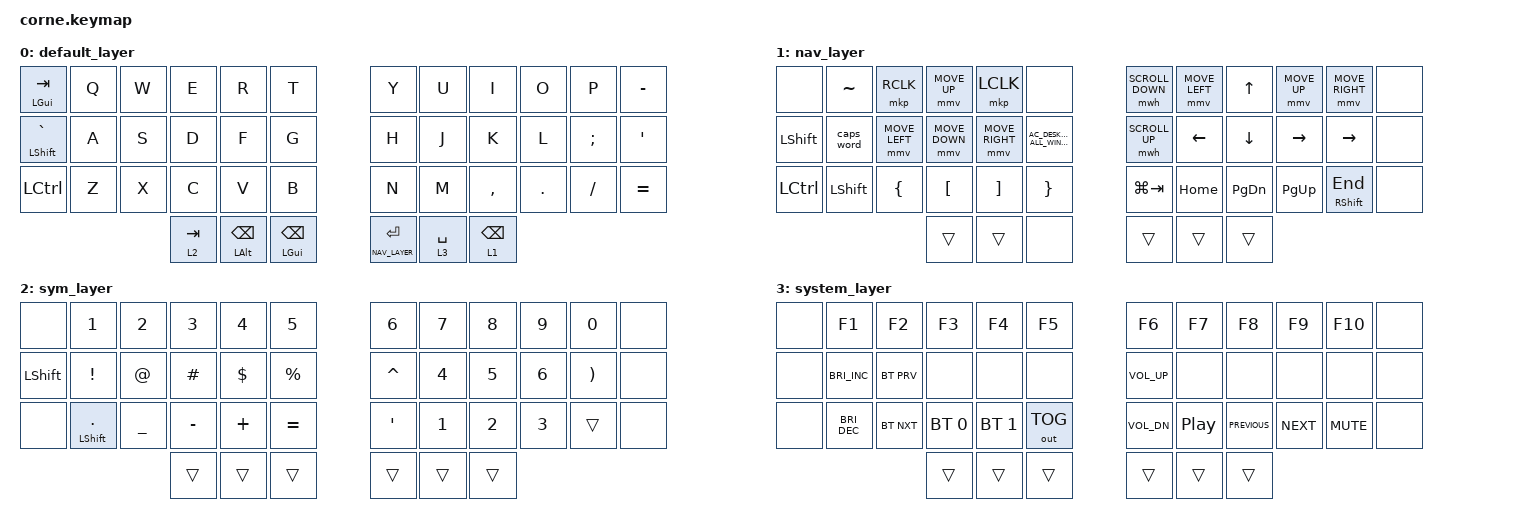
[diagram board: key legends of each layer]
/*
 * Copyright (c) 2020 The ZMK Contributors
 *
 * SPDX-License-Identifier: MIT
 */

#include <behaviors.dtsi>
#include <dt-bindings/zmk/mouse.h>
#include <dt-bindings/zmk/bt.h>
#include <dt-bindings/zmk/keys.h>
#include <dt-bindings/zmk/outputs.h>

#undef MOVE_UP
#undef MOVE_DOWN
#undef MOVE_LEFT
#undef MOVE_RIGHT

#define MOVE_UP MOVE_VERT(-6000)
#define MOVE_DOWN MOVE_VERT(6000)
#define MOVE_LEFT MOVE_HOR(-6000)
#define MOVE_RIGHT MOVE_HOR(6000)

#undef SCROLL_UP
#undef SCROLL_DOWN

#define SCROLL_UP SCROLL_VERT(40)
#define SCROLL_DOWN SCROLL_VERT(-40)
#define NAV_LAYER 1
#define SYM_LAYER 2
#define SYSTEM_LAYER 3

&mmv { time-to-max-speed-ms = <500>; };

&mwh { time-to-max-speed-ms = <500>; };

/ {
    behaviors {
        ht: holdtap {
            compatible = "zmk,behavior-hold-tap";
            label = "THUMB_HOLD_TAPS";
            #binding-cells = <2>;
            tapping-term-ms = <300>;
            flavor = "balanced";
            global-quick-tap;
            quick-tap-ms = <0>;
            bindings = <&kp>, <&kp>;
        };
    };

    macros {
        ae: ae {
            label = "ä";
            compatible = "zmk,behavior-macro";
            #binding-cells = <0>;
            wait-ms = <40>;
            tap-ms = <40>;
            bindings =
                <&macro_press>,
                <&kp LALT>,
                <&macro_tap>,
                <&kp U>,
                <&macro_release>,
                <&kp LALT>,
                <&macro_tap>,
                <&kp A>;
        };

        oe: oe {
            label = "ö";
            compatible = "zmk,behavior-macro";
            #binding-cells = <0>;
            wait-ms = <40>;
            tap-ms = <40>;
            bindings =
                <&macro_press>,
                <&kp LALT>,
                <&macro_tap>,
                <&kp U>,
                <&macro_release>,
                <&kp LALT>,
                <&macro_tap>,
                <&kp O>;
        };

        cae: cae {
            label = "Ä";
            compatible = "zmk,behavior-macro";
            #binding-cells = <0>;
            wait-ms = <40>;
            tap-ms = <40>;
            bindings =
                <&macro_press>,
                <&kp LALT>,
                <&macro_tap>,
                <&kp U>,
                <&macro_release>,
                <&kp LALT>,
                <&macro_press>,
                <&kp LSHFT>,
                <&macro_tap>,
                <&kp A>,
                <&macro_release>,
                <&kp LSHFT>;
        };

        coe: coe {
            label = "Ö";
            compatible = "zmk,behavior-macro";
            #binding-cells = <0>;
            wait-ms = <40>;
            tap-ms = <40>;
            bindings =
                <&macro_press>,
                <&kp LALT>,
                <&macro_tap>,
                <&kp U>,
                <&macro_release>,
                <&kp LALT>,
                <&macro_press>,
                <&kp LSHFT>,
                <&macro_tap>,
                <&kp O>,
                <&macro_release>,
                <&kp LSHFT>;
        };
    };

    combos {
        compatible = "zmk,combos";

        combo_mo1 {
            timeout-ms = <50>;
            key-positions = <39 40>;
            bindings = <&mo SYSTEM_LAYER>;
        };
    };

    keymap {
        compatible = "zmk,keymap";

        default_layer {
            bindings = <
&ht LEFT_GUI TAB      &kp Q  &kp W  &kp E      &kp R                   &kp T                &kp Y                &kp U        &kp I            &kp O    &kp P          &kp MINUS
&ht LEFT_SHIFT GRAVE  &kp A  &kp S  &kp D      &kp F                   &kp G                &kp H                &kp J        &kp K            &kp L    &kp SEMICOLON  &kp SQT
&kp LCTRL             &kp Z  &kp X  &kp C      &kp V                   &kp B                &kp N                &kp M        &kp COMMA        &kp DOT  &kp SLASH      &kp EQUAL
                                    &lt 2 TAB  &ht LEFT_ALT BACKSPACE  &ht LEFT_GUI BSPC    &lt NAV_LAYER ENTER  &lt 3 SPACE  &lt 1 BACKSPACE
            >;
        };

        nav_layer {
            bindings = <
&none             &kp TILDE   &mkp RCLK  &mmv MOVE_UP  &mkp LCLK  &none                                &mwh SCROLL_DOWN  &mmv MOVE_LEFT  &kp UP_ARROW  &mmv MOVE_UP  &mmv MOVE_RIGHT  &none
&kp LEFT_SHIFT    &caps_word  &mmv MOVE_LEFT      &mmv MOVE_DOWN        &mmv MOVE_RIGHT        &kp C_AC_DESKTOP_SHOW_ALL_WINDOWS    &mwh SCROLL_UP    &kp LEFT        &kp DOWN      &kp RIGHT     &kp RIGHT        &none
&kp LEFT_CONTROL  &kp LSHFT   &kp LBRC   &kp LBKT              &kp RBKT               &kp RBRC                             &kp LG(TAB)       &kp HOME        &kp PG_DN     &kp PG_UP     &ht RSHFT END    &none
                                         &trans                &trans                 &none                                &trans            &trans          &trans
            >;
        };

        sym_layer {
            bindings = <
&none           &kp N1         &kp N2     &kp N3     &kp N4    &kp N5       &kp N6     &kp N7        &kp N8        &kp N9        &kp N0    &none
&kp LEFT_SHIFT  &kp EXCL       &kp AT     &kp HASH   &kp DLLR  &kp PRCNT    &kp CARET  &kp NUMBER_4  &kp N5        &kp NUMBER_6  &kp RPAR  &none
&none           &ht LSHFT DOT  &kp UNDER  &kp MINUS  &kp PLUS  &kp EQUAL    &kp APOS   &kp NUMBER_1  &kp NUMBER_2  &kp NUMBER_3  &trans    &none
                                          &trans     &trans    &trans       &trans     &trans        &trans
            >;
        };

        system_layer {
            bindings = <
&none  &kp F1                &kp F2      &kp F3        &kp F4        &kp F5          &kp F6        &kp F7            &kp F8          &kp F9      &kp F10     &none
&none  &kp C_BRIGHTNESS_INC  &bt BT_PRV  &none         &none         &none           &kp C_VOL_UP  &none             &none           &none       &none       &none
&none  &kp C_BRIGHTNESS_DEC  &bt BT_NXT  &bt BT_SEL 0  &bt BT_SEL 1  &out OUT_TOG    &kp C_VOL_DN  &kp C_PLAY_PAUSE  &kp C_PREVIOUS  &kp C_NEXT  &kp K_MUTE  &none
                                         &trans        &trans        &trans          &trans        &trans            &trans
            >;
        };
    };
};
